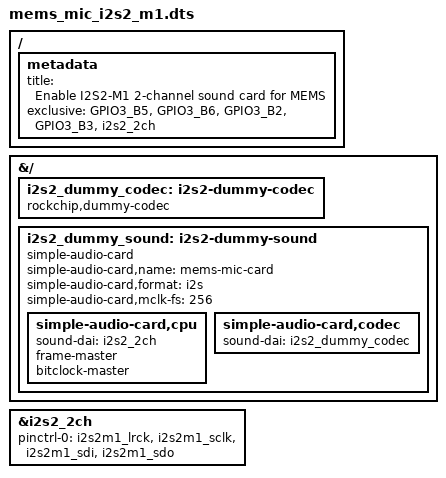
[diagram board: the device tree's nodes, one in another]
/dts-v1/;
/plugin/;

/ {
    metadata {
        title = "Enable I2S2-M1 2-channel sound card for MEMS";
        exclusive = "GPIO3_B5", "GPIO3_B6", "GPIO3_B2", "GPIO3_B3", "i2s2_2ch";
    };
};

&{/} {
    i2s2_dummy_codec: i2s2-dummy-codec {
        compatible = "rockchip,dummy-codec";
        #sound-dai-cells = <0>;
    };

    i2s2_dummy_sound: i2s2-dummy-sound {
        compatible = "simple-audio-card";
        simple-audio-card,name = "mems-mic-card";
        simple-audio-card,format = "i2s";
        simple-audio-card,mclk-fs = <256>;
        status = "okay";

        simple-audio-card,cpu {
            sound-dai = <&i2s2_2ch>;
            // Forces the RK3588 to generate SCLK and LRCK
            frame-master;
            bitclock-master;
        };

        simple-audio-card,codec {
            sound-dai = <&i2s2_dummy_codec>;
        };
    };
};

&i2s2_2ch {
    pinctrl-names = "default";
    pinctrl-0 = <&i2s2m1_lrck &i2s2m1_sclk &i2s2m1_sdi &i2s2m1_sdo>;
    status = "okay";
};
